# TF5103_v1 register map
File version: 1.0
Registers are 32-bit, read-write, reset 0x0 unless marked. A register's access mark holds for its fields unless they carry their own. Offsets are from the block's base; [hi:lo] are bit positions; {n}, {i} and the like mark numbered series; 'fields as' and 'values as' point back to an identical list.

## TMR — TMR Register Map
Base 0x40010000
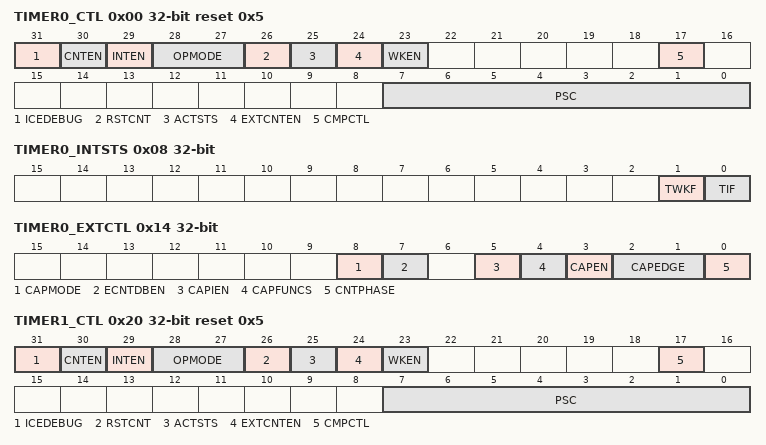
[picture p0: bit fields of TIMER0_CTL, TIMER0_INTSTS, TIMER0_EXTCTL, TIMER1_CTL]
0x00 TIMER0_CTL reset 0x5 — Timer0 Control and Status Register
  [31] ICEDEBUG — ICE Debug Mode Acknowledge Disable Control (Write Protect). Timer counter will keep going no matter CPU is held by ICE or not.
    0=ICE debug mode acknowledgement effects TIMER counting; 1=ICE debug mode acknowledgement Disabled
  [30] CNTEN — Timer Enable Control
    0=Stops/Suspends counting; 1=Starts counting
  [29] INTEN — Interrupt Enable Control. Note: If this bit is enabled, when the timer interrupt flag (TIF) is set to 1, the timer interrupt signal is generated and inform to CPU.
    0=Timer Interrupt function Disabled; 1=Timer Interrupt function Enabled
  [28:27] OPMODE — Timer Operating Mode
    0=The timer is operating in One-shot mode. The associated interrupt signal is generated once (if INTEN is enabled) and CNTEN is automatically cleared by hardware; 1=The timer is operating in Periodic mode. The associated interrupt signal is generated periodically (if INTEN is enabled); 2=The timer is operating in Toggle mode. The interrupt signal is generated periodically (if INTEN is enabled). The associated signal (tout) is changing back and forth with 50% duty cycle; 3=The timer is operating in Continuous Counting mode. The associated interrupt signal is generated when TIMERx_CNT = TIMERx_CMP (if INTEN is enabled). However, the 24-bit up-timer counts continuously. Please refer to 6.12.5.2 for detailed description about Continuous Counting mode operation
  [26] RSTCNT — Timer Reset
    0=No effect; 1=Reset 8-bit PSC counter, 24-bit up counter value and CNTEN bit if ACTSTS is 1
  [25] ACTSTS ro — Timer Active Status (Read Only). This bit indicates the 24-bit up counter status.
    0=24-bit up counter is not active; 1=24-bit up counter is active
  [24] EXTCNTEN — Counter Mode Enable Control. This bit is for external counting pin function enabled. When timer is used as an event counter, this bit should be set to 1 and select HCLK as timer clock source. Please refer to section 'Event Counting Mode' for detail description.
    0=External event counter mode Disabled; 1=External event counter mode Enabled
  [23] WKEN — Wake-up Enable Control. When WKEN is set and the TIF or CAPIF is set, the timer controller will generator a wake-up trigger event to CPU.
    0=Wake-up trigger event Disabled; 1=Wake-up trigger event Enabled
  [17] CMPCTL — TIMERx_CMP Mode Control
    0=In One-shot or Periodic mode, when write new CMPDAT, timer counter will reset; 1=In One-shot or Periodic mode, when write new CMPDAT if new CMPDAT CNT (TIMERx_CNT[23:0])(current counter) , timer counter keep counting and will not reset. If new CMPDAT = CNT(current counter) , timer counter will reset
  [7:0] PSC — Prescale Counter
0x04 TIMER0_CMP — Timer0 Compare Register
  [23:0] CMPDAT — Timer Compared Value. CMPDAT is a 24-bit compared value register. When the internal 24-bit up counter value is equal to CMPDAT value, the TIF flag will set to 1. Note1: Never write 0x0 or 0x1 in CMPDAT field, or the core will run into unknown state. Note2: When Timer is operating at Continuous Counting mode, the 24-bit up counter will keep counting continuously even if software writes a new value into CMPDAT field. But if Timer is operating at other modes except Periodic mode on M05xxDN/DE, the 24-bit up counter will restart counting and using newest CMPDAT value to be the timer compared value if software writes a new value into CMPDAT field.
0x08 TIMER0_INTSTS — Timer0 Interrupt Status Register
  [1] TWKF — Timer Wake-up Flag. This bit indicates the interrupt wake-up flag status of Timer. Note: This bit is cleared by writing 1 to it.
    0=Timer does not cause chip wake-up; 1=Chip wake-up from Idle or Power-down mode if Timer time-out interrupt signal generated
  [0] TIF — Timer Interrupt Flag. This bit indicates the interrupt flag status of Timer while CNT (TIMERx_CNT[23:0]) value reaches to CMPDAT value. Note: This bit is cleared by writing 1 to it.
    0=No effect; 1=CNT value matches the CMPDAT value
0x0C TIMER0_CNT ro — Timer0 Data Register
  [23:0] CNT — Timer Data Register. If CNTEN is set to 1, CNT register value will be updated continuously to monitor 24-bit up counter value.
0x10 TIMER0_CAP ro — Timer0 Capture Data Register
  [23:0] CAPDAT — Timer Capture Data Register. When CAPEN (TIMERx_EXTCTL[3]) bit is set, CAPFUNCS (TIMERx_EXTCTL[4]) bit is 0, and a transition on ACMPOx matched the CAPEDGE (TIMERx_EXTCTL[2:1]) setting, CAPIF (TIMERx_EINTSTS[0]) will set to 1 and the current timer counter value CNT (TIMERx_CNT[23:0]) will be auto-loaded into this CAPDAT field.
0x14 TIMER0_EXTCTL — Timer0 Extended Event Control Register
  [8] CAPMODE — Capture Mode Select Bit
    0=Timer counter reset function or free-counting mode of timer capture function; 1=Trigger-counting mode of timer capture function
  [7] ECNTDBEN — Timer Counter Input Pin De-bounce Enable Control
    0=TMx (x = 0~1) pin de-bounce Disabled; 1=TMx (x = 0~1) pin de-bounce Enabled
  [5] CAPIEN — Timer Capture Interrupt Enable Control
    0=Timer Capture Interrupt Disabled; 1=Timer Capture Interrupt Enabled
  [4] CAPFUNCS — Capture Function Select Bit. Note1: When CAPFUNCS is 0, transition on ACMPOx is using to save the 24-bit timer counter value to CAPDAT register. Note2: When CAPFUNCS is 1, transition on ACMPOx is using to reset the 24-bit timer counter value.
    0=Capture Mode Enabled; 1=Reset Mode Enabled
  [3] CAPEN — Timer Capture Function Enable Control. This bit enables the Timer Capture Function
    0=Timer Capture Function Disabled; 1=Timer Capture Function Enabled
  [2:1] CAPEDGE — Timer Capture Pin Edge Detection
    0=A falling edge on ACMP_COx will be detected; 1=A rising edge on ACMP_CO1 will be detected; 2=Either rising or falling edge on ACMP_COx will be detected
  [0] CNTPHASE — Timer External Count Pin Phase Detect Selection
    0=A falling edge of TMx (x = 0~3) pin will be counted; 1=A rising edge of TMx (x = 0~3) pin will be counted
0x18 TIMER0_EINTSTS — Timer0 Extended Event Interrupt Status Register
  [0] CAPIF — Timer Capture Interrupt Flag. This bit indicates the timer external capture interrupt flag status. Note1: This bit is cleared by writing 1 to it. Note2: When CAPEN (TIMERx_EXTCTL[3]) bit is set, CAPFUNCS (TIMERx_EXTCTL[4]) bit is 0, and a transition on ACMPOx matched the CAPEDGE (TIMERx_EXTCTL[2:1]) setting, this bit will set to 1 by hardware. Note3: There is a new incoming capture event detected before CPU clearing the CAPIF status. If the above condition occurred, the Timer will keep register TIMERx_CAP unchanged and drop the new capture value.
    0=Timer Capture interrupt did not occur; 1=Timer Capture interrupt occurred
0x20 TIMER1_CTL reset 0x5 — Timer1 Control and Status Register
  fields as TIMER0_CTL
0x24 TIMER1_CMP — Timer1 Compare Register
  fields as TIMER0_CMP
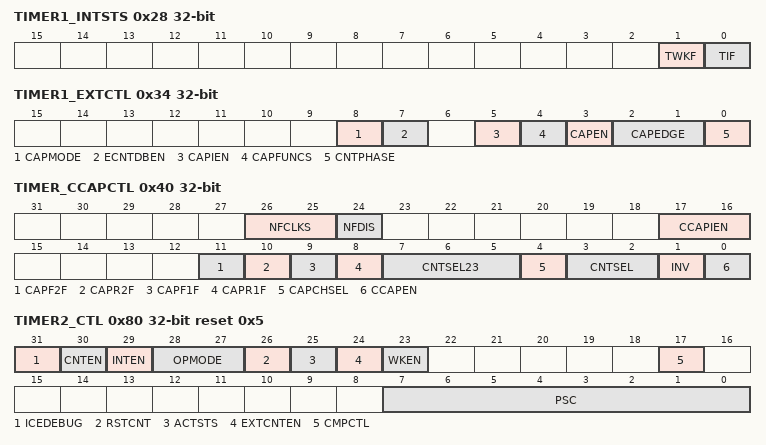
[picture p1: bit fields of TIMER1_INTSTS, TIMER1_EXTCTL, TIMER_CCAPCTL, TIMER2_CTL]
0x28 TIMER1_INTSTS — Timer1 Interrupt Status Register
  fields as TIMER0_INTSTS
0x2C TIMER1_CNT ro — Timer1 Data Register
  fields as TIMER0_CNT
0x30 TIMER1_CAP ro — Timer1 Capture Data Register
  fields as TIMER0_CAP
0x34 TIMER1_EXTCTL — Timer1 Extended Event Control Register
  fields as TIMER0_EXTCTL
0x38 TIMER1_EINTSTS — Timer1 Extended Event Interrupt Status Register
  fields as TIMER0_EINTSTS
0x40 TIMER_CCAPCTL — Timer Continuous Capture Control Register
  [26:25] NFCLKS — Noise Filter Clock Pre-divided Selection. To determine the sampling frequency of the Noise Filter clock
    0=CAPCLK; 1=CAPCLK / 2; 2=CAPCLK / 4; 3=CAPCLK / 16
  [24] NFDIS — Disable Input Capture Noise Filter
    0=Noise filter of Input Capture Enabled; 1=The noise filter of Input Capture Disabled
  [17:16] CCAPIEN — Capture Interrupt Enable Control
    0=Interrupt Disabled; 1=Capture Rising Edge 1 and Falling Edge 1 interrupt Enabled; 2=Capture Rising Edge 1, Falling dege1 and Rising Edge 2 interrupt Enabled; 3=Capture Rising Edge 1, Falling dege1, Rising Edge 2 and Falling Edge 2 interrupt Enabled
  [11] CAPF2F — Capture Falling Edge 2 Flag. Second falling edge already captured, this bit will be set to 1. Note: This bit is cleared by hardware automatically when writing 1 to this bit.
    0=None; 1=CAPDAT(TIMER_CCAP3[23:0]) data is ready for read
  [10] CAPR2F — Capture Rising Edge 2 Flag. Second rising edge already captured, this bit will be set to 1. Note: This bit is cleared by hardware automatically when writing 1 to this bit.
    0=None; 1=CAPDAT(TIMER_CCAP2[23:0]) data is ready for read
  [9] CAPF1F — Capture Falling Edge 1 Flag. First falling edge already captured, this bit will be set to 1. Note: This bit is cleared by hardware automatically when writing 1 to this bit.
    0=None; 1=CAPDAT(TIMER_CCAP1[23:0]) data is ready for read
  [8] CAPR1F — Capture Rising Edge 1 Flag. First rising edge already captured, this bit will be set to 1. Note: This bit is cleared by hardware automatically when writing 1 to this bit.
    0=None; 1=CAPDAT(TIMER_CCAP0[23:0]) data is ready for read
  [7:5] CNTSEL23 — Capture Timer23 Selection
    0=TIMER2; 1=TIMER3
  [4] CAPCHSEL — Capture Timer Channel Selection. Select the channel to be the continuous capture event.
    0=CCAP_P0; 1=CCAP_P1
  [3:2] CNTSEL — Capture Timer Selection. Select the timer to continuous capture the input signal.
    0=TIMER0; 1=TIMER1; 2=SysTick; 3=See CNTSEL23
  [1] INV — Input Signal Inverse. Invert the input signal which be captured.
    0=None; 1=Inverse
  [0] CCAPEN — Continuous Capture Enable Control. This bit is to be enabled the continuous capture function. Note: This bit is cleared by hardware automatically when capture operation finish or writing 0 to it
    0=Disabled Continuous capture function; 1=Enabled Continuous capture function
{0x44+4i} TIMER_CCAP{i} ro (i=0..3) — Timer Continuous Capture Data Register {i}
  [23:0] CAPDAT — Timer Continuous Capture Data Register. TIMER_CCAP0 store the timer count value of first rising edge. TIMER_CCAP1 store the timer count value of first falling edge. TIMER_CCAP2 store the timer count value of second rising edge. TIMER_CCAP3 store the timer count value of second falling edge
0x80 TIMER2_CTL reset 0x5 — Timer2 Control and Status Register
  fields as TIMER0_CTL
0x84 TIMER2_CMP — Timer2 Compare Register
  fields as TIMER0_CMP
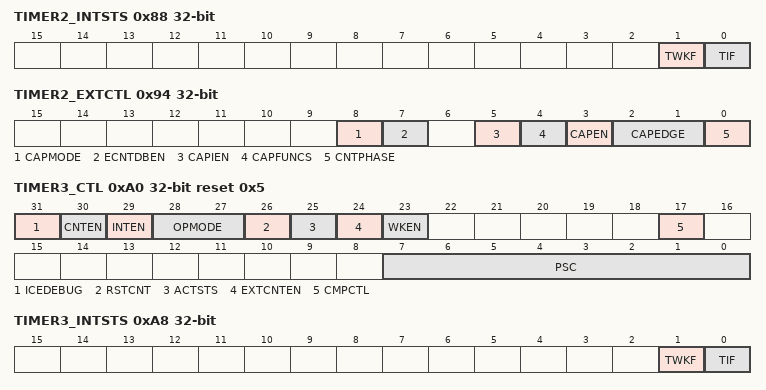
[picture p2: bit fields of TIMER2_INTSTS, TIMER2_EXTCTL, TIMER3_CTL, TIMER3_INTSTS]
0x88 TIMER2_INTSTS — Timer2 Interrupt Status Register
  fields as TIMER0_INTSTS
0x8C TIMER2_CNT ro — Timer2 Data Register
  fields as TIMER0_CNT
0x90 TIMER2_CAP ro — Timer2 Capture Data Register
  fields as TIMER0_CAP
0x94 TIMER2_EXTCTL — Timer2 Extended Event Control Register
  fields as TIMER0_EXTCTL
0x98 TIMER2_EINTSTS — Timer2 Extended Event Interrupt Status Register
  fields as TIMER0_EINTSTS
0xA0 TIMER3_CTL reset 0x5 — Timer3 Control and Status Register
  fields as TIMER0_CTL
0xA4 TIMER3_CMP — Timer3 Compare Register
  fields as TIMER0_CMP
0xA8 TIMER3_INTSTS — Timer3 Interrupt Status Register
  fields as TIMER0_INTSTS
0xAC TIMER3_CNT ro — Timer3 Data Register
  fields as TIMER0_CNT
0xB0 TIMER3_CAP ro — Timer3 Capture Data Register
  fields as TIMER0_CAP
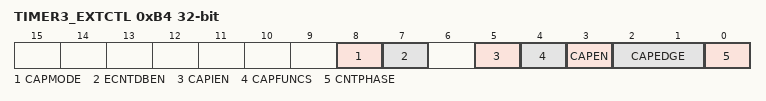
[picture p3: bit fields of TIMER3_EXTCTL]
0xB4 TIMER3_EXTCTL — Timer3 Extended Event Control Register
  fields as TIMER0_EXTCTL
0xB8 TIMER3_EINTSTS — Timer3 Extended Event Interrupt Status Register
  fields as TIMER0_EINTSTS
